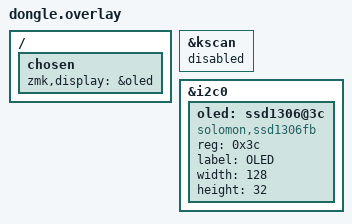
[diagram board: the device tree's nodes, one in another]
/ {
    chosen {
        zmk,display = &oled;
    };
};

/* Disable matrix scanning */
&kscan {
    status = "disabled";
};

/* I2C OLED */
&i2c0 {
    status = "okay";

    oled: ssd1306@3c {
        compatible = "solomon,ssd1306fb";
        reg = <0x3c>;
        label = "OLED";
        width = <128>;
        height = <32>; /* or 64 depending on your screen */
    };
};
